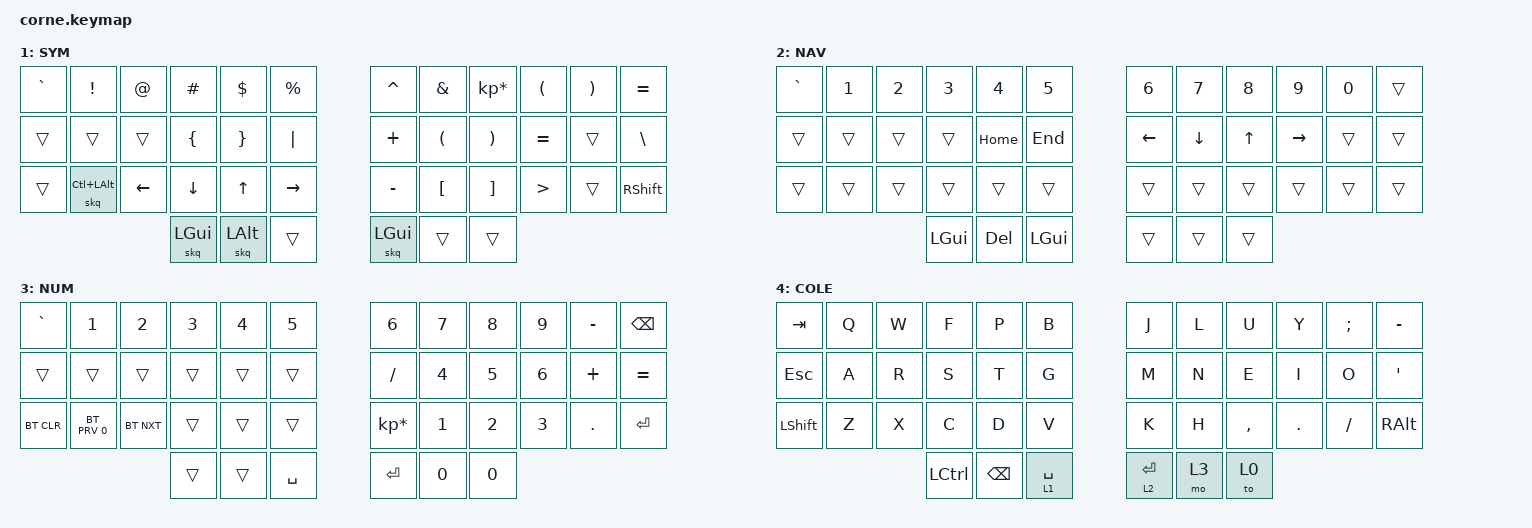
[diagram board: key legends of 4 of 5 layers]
/*
 * Copyright (c) 2020 The ZMK Contributors
 *
 * SPDX-License-Identifier: MIT
 */

#include <behaviors.dtsi>
#include <dt-bindings/zmk/keys.h>
#include <dt-bindings/zmk/bt.h>

&mt {
    flavor = "tap-preferred";
    tapping_term_ms = <200>;
};

/ {
        behaviors {
                skq: sticky_key_quick_release {
                        compatible = "zmk,behavior-sticky-key";
                        label = "STICKY_KEY_QUICK_RELEASE";
                        #binding-cells = <1>;
                        bindings = <&kp>;
                        release-after-ms = <1000>;
                        quick-release;
                        ignore-modifiers;
                };
                gqt: global-quick-tap {
                        compatible = "zmk,behavior-hold-tap";
                        label = "GLOBAL_QUICK_TAP";
                        #binding-cells = <2>;
                        flavor = "tap-preferred";
                        tapping-term-ms = <200>;
                        quick-tap-ms = <125>;
                        global-quick-tap;
                        bindings = <&kp>, <&kp>;
                };
        };

        keymap {
                compatible = "zmk,keymap";

                layer_Base {
// -----------------------------------------------------------------------------------------
// |  TAB |  Q  |  W  |  E      |    R    |    T    |   |    Y    |  U   |  I   |  O  |  P  |  -  |
// |  ESC |  A  |  S  |  D      |    F    |    G    |   |    H    |  J   |  K   |  L  |  ;  |  '  |
// | SHFT |  Z  |  X  |  C/COPY | V/PASTE |    B    |   |    N    |  M   |  ,   |  .  |  /  | ALT |
//                    |  CTRL   |  BKSP   | SPC/SYM |   | ENT/NAV | NUM  | COLE |
                        bindings = <
   &kp TAB   &kp Q &kp W &kp E        &kp R        &kp T           &kp Y     &kp U  &kp I     &kp O   &kp P    &kp MINUS
   &kp ESC   &kp A    &kp S &kp D        &kp F        &kp G           &kp H     &kp J  &kp K     &kp L   &kp SEMI &kp SQT
   &kp LSHFT &kp Z    &kp X &kp C  &kp V  &kp B           &kp N     &kp M  &kp COMMA &kp DOT &kp FSLH &kp RALT
                            &kp LCTRL    &kp BSPC     &lt &sl 1 SPACE &lt 2 RET &to 3  &to 4
                        >;
                        label = "BASE";
                };

                layer_Symbol {
// -----------------------------------------------------------------------------------------
// |  `  |     !    |  @  |  #  |  $  |  %  |   |  ^  |  &  |  *  |  (  |  )  |  =   |
// |     |          |     |  {  |  }  |  |  |   |  +  |  (  |  )  |  =  |     |  \   |
// |     | CTRL-ALT | LFT | DWN | UP  | RGT |   |  -  |  [  |  ]  |  >  |     | SHFT |
//                    | GUI | ALT |     |   | GUI |     |     |
                        bindings = <
   &kp GRAVE  &kp EXCL  &kp AT   &kp HASH &kp DLLR   &kp PRCNT   &kp CARET &kp AMPS  &kp KP_MULTIPLY &kp LPAR  &kp RPAR &kp EQUAL
   &trans     &trans    &trans   &kp LBRC &kp RBRC   &kp PIPE    &kp PLUS  &kp LPAR  &kp RPAR        &kp EQUAL &trans   &kp BSLH
   &trans &skq LC(LALT) &kp LEFT &kp DOWN &kp UP     &kp RIGHT   &kp MINUS &kp LBKT  &kp RBKT        &kp GT    &trans   &kp RSHFT
                    	         &skq LGUI &skq LALT &trans      &skq LGUI &trans    &trans
                        >;
                        label = "SYM";
                };

                layer_Nav {
// -----------------------------------------------------------------------------------------
// |  `  |  1  |  2  |  3  |  4   |  5  |   |  6  |  7  |  8  |  9  |  0  |      |
// |     |     |     |     | HOME | END |   | LFT | DWN |  UP | RGT |     |      |
// |     |     |     |     |      |     |   |     |     |     |     |     |      |
//                   | GUI | DEL  | GUI |   |     |     |     |
                        bindings = <
   &kp GRAVE  &kp N1    &kp N2  &kp N3   &kp N4   &kp N5    &kp N6   &kp N7   &kp N8 &kp N9    &kp N0 &trans
   &trans     &trans    &trans  &trans   &kp HOME &kp END   &kp LEFT &kp DOWN &kp UP &kp RIGHT &trans &trans
   &trans     &trans    &trans  &trans   &trans   &trans    &trans   &trans   &trans &trans    &trans &trans
              	        &kp LGUI &kp DEL &kp LGUI &trans    &trans   &trans
                        >;
                        label = "NAV";
                };

                layer_NumBT {
// -----------------------------------------------------------------------------------------
// |   `   |    1   |   2    |  3  |  4  |  5  |   |  6  |  7  |  8  |  9  |  -  |  BKSP |
// |       |        |        |     |     |     |   |  /  |  4  |  5  |  6  |  +  |   =   |
// | BTCLR | BT_PRV | BT_NXT |     |     |     |   |  *  |  1  |  2  |  3  |  .  |  RET  |
//                           |     |     | SPC |   | RET |  0  |  0  |
                        bindings = <
   &kp GRAVE  &kp N1       &kp N2       &kp N3       &kp N4       &kp N5         &kp N6          &kp N7 &kp N8 &kp N9 &kp MINUS &kp BSPC
   &trans     &trans       &trans       &trans       &trans       &trans         &kp FSLH        &kp N4 &kp N5 &kp N6 &kp PLUS  &kp EQUAL
   &bt BT_CLR &bt BT_PRV 0 &bt BT_NXT   &trans       &trans       &trans         &kp KP_MULTIPLY &kp N1 &kp N2 &kp N3 &kp DOT   &kp RET
                          	        &trans       &trans       &kp SPACE      &kp RET         &kp N0 &kp N0
                        >;
                        label = "NUM";
                };

                layer_ColemakDH {
// -----------------------------------------------------------------------------------------
// |  TAB |  Q  |  W  |  F   |  P   |    B    |   |    J    |  L  |  U   |  Y  |  ;  |  -  |
// |  ESC |  A  |  R  |  S   |  T   |    G    |   |    M    |  N  |  E   |  I  |  O  |  '  |
// | SHFT |  Z  |  X  |  C   |  D   |    V    |   |    K    |  H  |  ,   |  .  |  /  | ALT |
//                    | CTRL | BKSP | SPC/SYM |   | ENT/NAV | NUM | BASE |
                        bindings = <
   &kp TAB   &kp Q &kp W &kp F     &kp P    &kp B        &kp J     &kp L  &kp U     &kp Y   &kp SEMI &kp MINUS
   &kp ESC   &kp A &kp R &kp S     &kp T    &kp G        &kp M     &kp N  &kp E     &kp I   &kp O    &kp SQT
   &kp LSHFT &kp Z &kp X &kp C     &kp D    &kp V        &kp K     &kp H  &kp COMMA &kp DOT &kp FSLH &kp RALT
                         &kp LCTRL &kp BSPC &lt 1 SPACE  &lt 2 RET &mo 3  &to 0
                        >;
                        label = "COLE";
                };

        };
};
